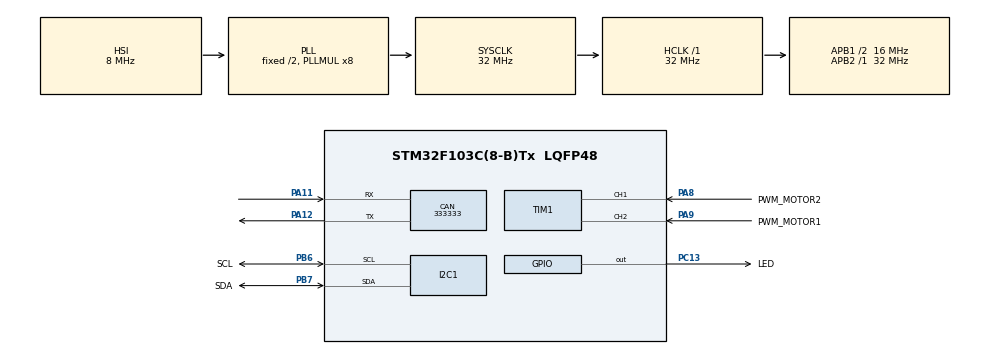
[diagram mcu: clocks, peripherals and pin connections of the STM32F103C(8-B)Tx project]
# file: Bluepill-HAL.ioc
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CAN.CalculateBaudRate=333333
CAN.CalculateTimeBit=3000
CAN.CalculateTimeQuantum=1000.0
Mcu.Family=STM32F1
Mcu.Name=STM32F103C(8-B)Tx
Mcu.Package=LQFP48
NVIC.PriorityGroup=NVIC_PRIORITYGROUP_4
PA11.Mode=CAN_Activate
PA11.Signal=CAN_RX
PA12.Mode=CAN_Activate
PA12.Signal=CAN_TX
PA13.Mode=Serial_Wire
PA13.Signal=SYS_JTMS-SWDIO
PA14.Mode=Serial_Wire
PA14.Signal=SYS_JTCK-SWCLK
PA8.GPIO_Label=PWM_MOTOR2
PA8.Signal=S_TIM1_CH1
PA9.GPIO_Label=PWM_MOTOR1
PA9.Signal=S_TIM1_CH2
PB6.GPIO_Label=SCL
PB6.Mode=I2C
PB6.Signal=I2C1_SCL
PB7.GPIO_Label=SDA
PB7.Mode=I2C
PB7.Signal=I2C1_SDA
PC13-TAMPER-RTC.GPIO_Label=LED
PC13-TAMPER-RTC.Signal=GPIO_Output
PD0-OSC_IN.Mode=HSE-External-Oscillator
PD0-OSC_IN.Signal=RCC_OSC_IN
PD1-OSC_OUT.Mode=HSE-External-Oscillator
PD1-OSC_OUT.Signal=RCC_OSC_OUT
ProjectManager.HeapSize=0x200
ProjectManager.StackSize=0x400
ProjectManager.TargetToolchain=CMake
RCC.AHBFreq_Value=32000000
RCC.APB1CLKDivider=RCC_HCLK_DIV2
RCC.APB1Freq_Value=16000000
RCC.APB1TimFreq_Value=32000000
RCC.APB2Freq_Value=32000000
RCC.APB2TimFreq_Value=32000000
RCC.HCLKFreq_Value=32000000
RCC.PLLMUL=RCC_PLL_MUL8
RCC.SYSCLKFreq_VALUE=32000000
RCC.SYSCLKSource=RCC_SYSCLKSOURCE_PLLCLK
RCC.USBFreq_Value=32000000
SH.S_TIM1_CH1.0=TIM1_CH1,Encoder_Interface
SH.S_TIM1_CH2.0=TIM1_CH2,Encoder_Interface
board=custom

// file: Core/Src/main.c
/* USER CODE BEGIN Header */
/**
  ******************************************************************************
  * @file           : main.c
  * @brief          : Main program body
  ******************************************************************************
  * @attention
  *
  * Copyright (c) 2024 STMicroelectronics.
  * All rights reserved.
  *
  * This software is licensed under terms that can be found in the LICENSE file
  * in the root directory of this software component.
  * If no LICENSE file comes with this software, it is provided AS-IS.
  *
  ******************************************************************************
  */
/* USER CODE END Header */
#include "main.h"
#include "can.h"
#include "i2c.h"
#include "tim.h"
#include "gpio.h"

/* USER CODE BEGIN Includes */
#include <../../Main/mainProgram.h>
/* USER CODE END Includes */

void SystemClock_Config(void);

int main(void)
{

  /* MCU Configuration--------------------------------------------------------*/

  /* Reset of all peripherals, Initializes the Flash interface and the Systick. */
  HAL_Init();

  /* Configure the system clock */
  SystemClock_Config();

  /* Initialize all configured peripherals */
  MX_GPIO_Init();
  MX_TIM1_Init();
  MX_CAN_Init();
  MX_I2C1_Init();
  /* USER CODE BEGIN 2 */
  mainProgram();
  /* USER CODE END 2 */

  /* Infinite loop */
  while (1)
  {

  }
}

void SystemClock_Config(void)
{
  RCC_OscInitTypeDef RCC_OscInitStruct = {0};
  RCC_ClkInitTypeDef RCC_ClkInitStruct = {0};

  /** Initializes the RCC Oscillators according to the specified parameters
  * in the RCC_OscInitTypeDef structure.
  */
  RCC_OscInitStruct.OscillatorType = RCC_OSCILLATORTYPE_HSI;
  RCC_OscInitStruct.HSIState = RCC_HSI_ON;
  RCC_OscInitStruct.HSICalibrationValue = RCC_HSICALIBRATION_DEFAULT;
  RCC_OscInitStruct.PLL.PLLState = RCC_PLL_ON;
  RCC_OscInitStruct.PLL.PLLSource = RCC_PLLSOURCE_HSI_DIV2;
  RCC_OscInitStruct.PLL.PLLMUL = RCC_PLL_MUL8;
  if (HAL_RCC_OscConfig(&RCC_OscInitStruct) != HAL_OK)
  {
    Error_Handler();
  }

  /** Initializes the CPU, AHB and APB buses clocks
  */
  RCC_ClkInitStruct.ClockType = RCC_CLOCKTYPE_HCLK|RCC_CLOCKTYPE_SYSCLK
                              |RCC_CLOCKTYPE_PCLK1|RCC_CLOCKTYPE_PCLK2;
  RCC_ClkInitStruct.SYSCLKSource = RCC_SYSCLKSOURCE_PLLCLK;
  RCC_ClkInitStruct.AHBCLKDivider = RCC_SYSCLK_DIV1;
  RCC_ClkInitStruct.APB1CLKDivider = RCC_HCLK_DIV2;
  RCC_ClkInitStruct.APB2CLKDivider = RCC_HCLK_DIV1;

  if (HAL_RCC_ClockConfig(&RCC_ClkInitStruct, FLASH_LATENCY_1) != HAL_OK)
  {
    Error_Handler();
  }
}

void Error_Handler(void)
{
  __disable_irq();
  while (1)
  {
  }
}
